# ATSAM4LC4B device description
Architecture: CORTEX-M4; Family: SAM4; Series: SAM4L
Registers are 32-bit, read-write, reset 0x0 unless marked. A register's access mark holds for its fields unless they carry their own. Offsets are from the block's base; [hi:lo] are bit positions; lines under a group give offsets from that group; {n}, {i} and the like mark numbered series; 'fields as' and 'values as' point back to an identical list.

## USERPAGE_FUSES — Non-Volatile Fuses
Instances: USERPAGE_FUSES 0x00800000
0x00 USERPAGE_WORD_1 reset 0xFFFFFFFF
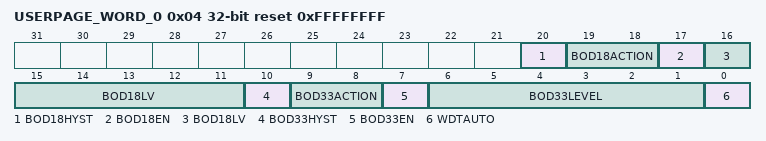
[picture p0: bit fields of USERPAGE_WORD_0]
0x04 USERPAGE_WORD_0 reset 0xFFFFFFFF
  [20] BOD18HYST — 1v8 Brown Out Detector Hysteresis
    0=BOD_HYST_DISABLED (Disabled); 1=BOD_HYST_ENABLED (Enabled)
  [19:18] BOD18ACTION — 1v8 Brown Out Detector Action
    0=BOD_ACTION_NOACTION (BOD No Action); 1=BOD_ACTION_GENERATE_RESET (The BOD generates a reset); 2=BOD_ACTION_GENERATE_INTERRUPT (The BOD generates an interrupt); 3=BOD_ACTION_RESERVED (Reserved)
  [17] BOD18EN — 1v8 Brown Out Detector Enable
    0=BOD_DISABLED; 1=BOD_ENABLED
  [16:11] BOD18LV — 1v8 Brown Out Detector Level
    0=BOD_LEVEL_OFF; 31=BOD_LEVEL_1V56 (BOD Level 1.56V); 39=BOD_LEVEL_1V65 (BOD Level 1.65V)
  [10] BOD33HYST — 3v3 Brown Out Detector Hysteresis
    0=BOD_HYST_DISABLED (Disabled); 1=BOD_HYST_ENABLED (Enabled)
  [9:8] BOD33ACTION — 3v3 Brown Out Detector Action
    values as BOD18ACTION
  [7] BOD33EN — 3v3 Brown Out Detector Enable
    0=BOD_DISABLED; 1=BOD_ENABLED
  [6:1] BOD33LEVEL — 3v3 Brown Out Detector Level
    values as BOD18LV
  [0] WDTAUTO — Watch dog timer auto enable/disable at startup
    0=WDT_ENABLE (WDT is automatically enabled at startup); 1=WDT_DISABLE (WDT is not automatically enabled at startup)

## FLASH_FUSES — Non-Volatile Fuses
Instances: FLASH_FUSES 0x400A0000 in fuses
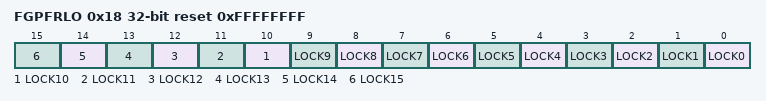
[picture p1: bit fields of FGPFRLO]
0x18 FGPFRLO reset 0xFFFFFFFF — Flash Controller General Purpose Fuse Register Low
  [n] LOCK{n} (n=0..15)

## FREQM — Frequency Meter
Instances: FREQM 0x400E0C00
0x00 CTRL wo — Control register
  [0] START — Start frequency measurement
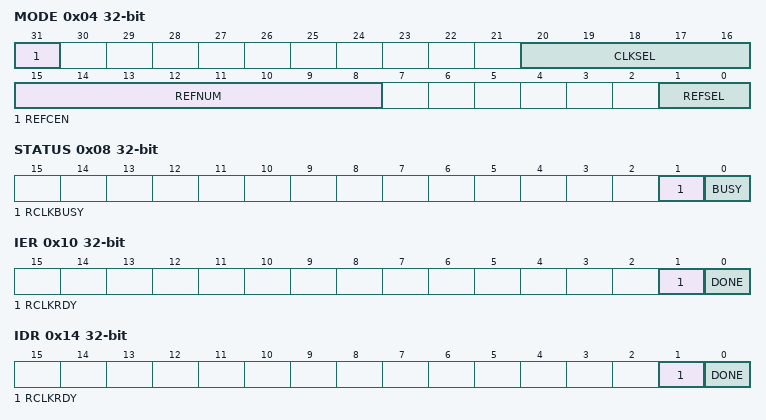
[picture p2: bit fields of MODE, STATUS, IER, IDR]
0x04 MODE
  [31] REFCEN — Reference Clock Enable
  [20:16] CLKSEL — Clock Source Selection
  [15:8] REFNUM — Number of Reference CLock Cycles
  [1:0] REFSEL — Reference Clock Selection
0x08 STATUS ro
  [1] RCLKBUSY — Reference Clock busy
  [0] BUSY — Frequency measurement on-going
0x0C VALUE ro
  [23:0] VALUE — Measured frequency
0x10 IER wo (atomic set of IMR) — Interrupt Enable Register
  [1] RCLKRDY — Reference Clock ready
  [0] DONE — Frequency measurment done
0x14 IDR wo (atomic clear of IMR) — Interrupt Diable Register
  fields as IER
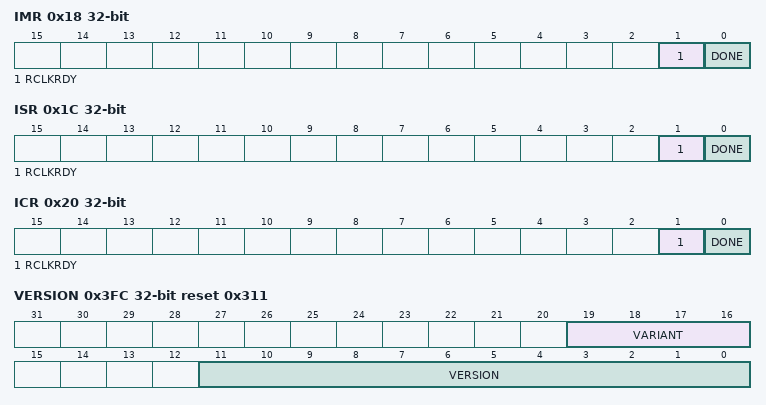
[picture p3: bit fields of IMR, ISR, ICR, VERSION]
0x18 IMR ro — Interrupt Mask Register
  fields as IER
0x1C ISR ro — Interrupt Status Register
  fields as IER
0x20 ICR wo (atomic clear of ISR) — Interrupt Clear Register
  fields as IER
0x3FC VERSION ro reset 0x311
  [19:16] VARIANT — Variant number
  [11:0] VERSION — Version number

## GLOC — Glue Logic Controller
Instances: GLOC 0x40060000
{0x0+8i} LUT[{i}] (i=0..1) group
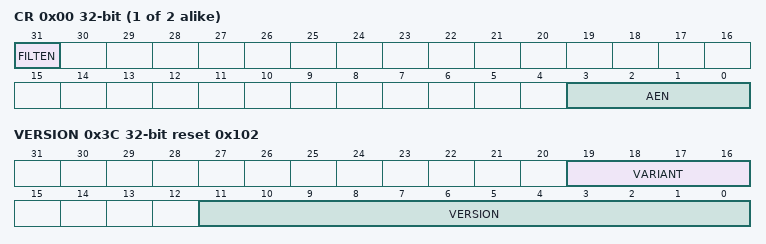
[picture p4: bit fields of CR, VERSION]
  0x00 CR — Control Register
    [31] FILTEN — Filter enable
    [3:0] AEN — Input mask
  0x04 TRUTH
    [15:0] TRUTH
0x38 PARAMETER ro reset not defined
  [7:0] LUTS
0x3C VERSION ro reset 0x102
  [19:16] VARIANT, [11:0] VERSION

## HCACHE — Cortex M I&D Cache Controller
Instances: HCACHE 0x400A0400
0x08 CTRL wo reset not defined — Control Register
  [0] CEN — Cache Enable
    0=NO (Disable Cache Controller); 1=YES (Enable Cache Controller)
0x0C SR reset not defined — Status Register
  [0] CSTS — Cache Controller Status
    0=DIS (Cache Controller Disabled); 1=EN (Cache Controller Enabled)
0x20 MAINT0 wo reset not defined — Maintenance Register 0
  [0] INVALL — Cache Controller Invalidate All
    0=NO (No effect); 1=YES (Invalidate all cache entries)
0x24 MAINT1 wo reset not defined — Maintenance Register 1
  [7:4] INDEX — Invalidate Index
0x28 MCFG reset not defined — Monitor Configuration Register
  [1:0] MODE — Cache Controller Monitor Counter Mode
    0=CYCLE (Cycle Counter); 1=IHIT (Instruction Hit Counter); 2=DHIT (Data Hit Counter)
0x2C MEN reset not defined — Monitor Enable Register
  [0] MENABLE — Monitor Enable
    0=DIS (Disable Monitor Counter); 1=EN (Enable Monitor Counter)
0x30 MCTRL wo reset not defined — Monitor Control Register
  [0] SWRST — Monitor Software Reset
    0=NO (No effect); 1=YES (Reset event counter register)
0x34 MSR ro reset not defined — Monitor Status Register
  [31:0] EVENTCNT — Monitor Event Counter
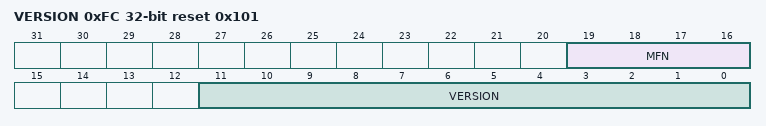
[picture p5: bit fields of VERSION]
0xFC VERSION ro reset 0x101
  [19:16] MFN, [11:0] VERSION

## Notices in the file
Copyright (c) 2016 Atmel Corporation,
a wholly owned subsidiary of Microchip Technology Inc.
Licensed under the Apache License, Version 2.0 (the "License");
you may not use this file except in compliance with the License.
You may obtain a copy of the Licence at
http://www.apache.org/licenses/LICENSE-2.0
Unless required by applicable law or agreed to in writing, software
distributed under the License is distributed on an "AS IS" BASIS,
WITHOUT WARRANTIES OR CONDITIONS OF ANY KIND, either express or implied.
See the License for the specific language governing permissions and
limitations under the License.
